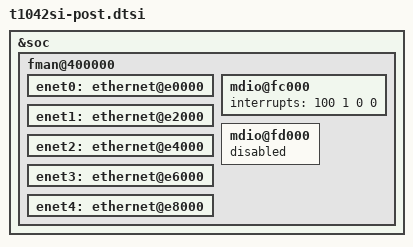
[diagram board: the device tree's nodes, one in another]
// SPDX-License-Identifier: (GPL-2.0+ OR BSD-3-Clause)
/*
 * T1042 Silicon/SoC Device Tree Source (post include)
 *
 * Copyright 2013 - 2014 Freescale Semiconductor Inc.
 * Copyright 2021-2023 NXP
 *
 */
&soc {
/include/ "qoriq-clockgen2.dtsi"
/include/ "qoriq-duart-0.dtsi"
/include/ "qoriq-duart-1.dtsi"
/include/ "qoriq-gpio-0.dtsi"
/include/ "qoriq-gpio-1.dtsi"
/include/ "qoriq-gpio-2.dtsi"
/include/ "qoriq-gpio-3.dtsi"
/include/ "qoriq-sec5.0-0.dtsi"

/include/ "qoriq-fman3l-0.dtsi"
/include/ "qoriq-fman3-0-1g-0.dtsi"
/include/ "qoriq-fman3-0-1g-1.dtsi"
/include/ "qoriq-fman3-0-1g-2.dtsi"
/include/ "qoriq-fman3-0-1g-3.dtsi"
/include/ "qoriq-fman3-0-1g-4.dtsi"
	fman@400000 {
		enet0: ethernet@e0000 {
		};

		enet1: ethernet@e2000 {
		};

		enet2: ethernet@e4000 {
		};

		enet3: ethernet@e6000 {
		};

		enet4: ethernet@e8000 {
		};

		mdio@fc000 {
			interrupts = <100 1 0 0>;
		};

		mdio@fd000 {
			status = "disabled";
		};
	};
};
